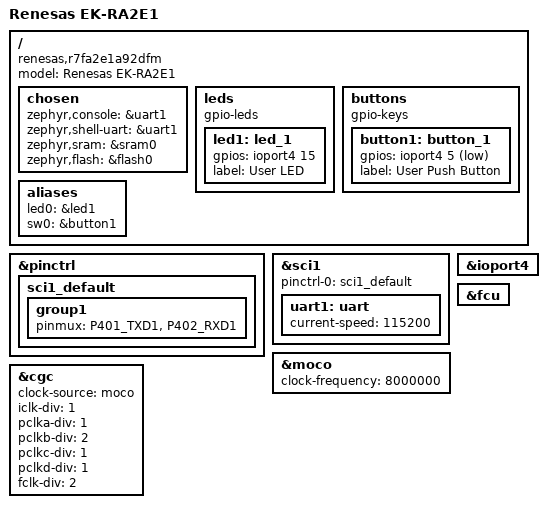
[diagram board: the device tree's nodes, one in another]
/*
 * Copyright (c) 2024 Ian Morris
 *
 * SPDX-License-Identifier: Apache-2.0
 */

 /dts-v1/;
 #include <renesas/ra/r7fa2e1a92dfm.dtsi>
 #include <zephyr/dt-bindings/pinctrl/renesas/pinctrl-r7fa2e1xxxxxx.h>
 #include <zephyr/dt-bindings/gpio/gpio.h>

 / {
	model = "Renesas EK-RA2E1";
	compatible = "renesas,r7fa2e1a92dfm";

	chosen {
		zephyr,console = &uart1;
		zephyr,shell-uart = &uart1;
		zephyr,sram = &sram0;
		zephyr,flash = &flash0;
	};

	leds {
		compatible = "gpio-leds";
		led1: led_1 {
			gpios = <&ioport4 15 GPIO_ACTIVE_HIGH>;
			label = "User LED";
		};
	};

	buttons {
		compatible = "gpio-keys";
		button1: button_1 {
			gpios = <&ioport4 5 (GPIO_PULL_UP | GPIO_ACTIVE_LOW)>;
			label = "User Push Button";
		};
	};

	aliases {
		led0 = &led1;
		sw0 = &button1;
	};
 };

&pinctrl {
	sci1_default: sci1_default {
		group1 {
			pinmux = <P401_TXD1>, <P402_RXD1>;
		};
	};
};

&sci1 {
	status = "okay";
	pinctrl-0 = <&sci1_default>;
	pinctrl-names = "default";
	uart1: uart {
		current-speed = <115200>;
		status = "okay";
	};
};

&ioport4 {
	status = "okay";
};

&fcu {
	status = "okay";
};

&moco {
	status = "okay";
	clock-frequency = <8000000>;
};

&cgc {
	clock-source = <&moco>;
	iclk-div = <1>;
	pclka-div = <1>;
	pclkb-div = <2>;
	pclkc-div = <1>;
	pclkd-div = <1>;
	fclk-div = <2>;
};
